# STM32U599 register map
File version: 1.0
CPU: CM33 r0p1, little endian, MPU, FPU, 4 interrupt priority bits
Registers are 32-bit, read-write, reset 0x0 unless marked. A register's access mark holds for its fields unless they carry their own. Offsets are from the block's base; [hi:lo] are bit positions; {n}, {i} and the like mark numbered series.

## GTZC1_MPCBB1
Base 0x40032C00
Same registers: SEC_GTZC1_MPCBB1 0x50032C00
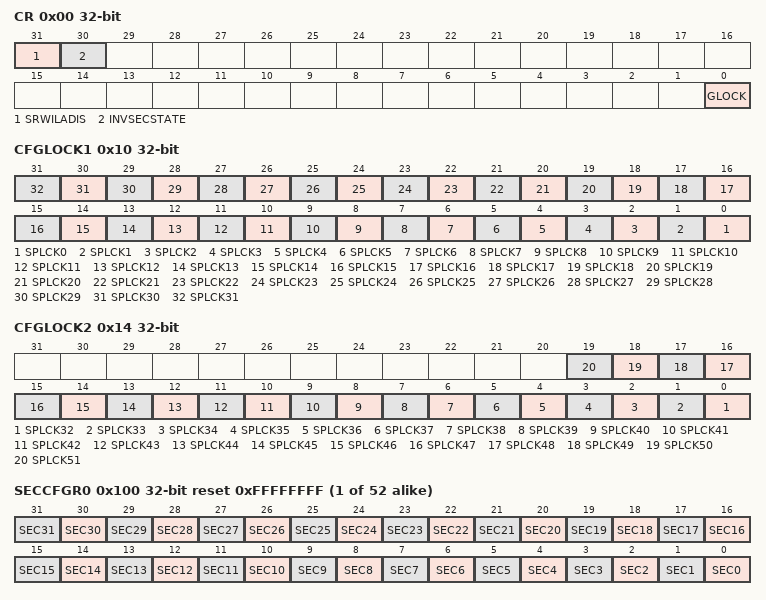
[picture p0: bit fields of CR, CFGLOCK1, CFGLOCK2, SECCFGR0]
0x00 CR — MPCBB control register
  [31] SRWILADIS — secure read/write illegal access disable
  [30] INVSECSTATE — SRAMx clocks security state
  [0] GLOCK — lock the control register of the MPCBB until next reset
0x10 CFGLOCK1 — GTZC1 SRAMz MPCBB configuration lock register 1
  [n] SPLCK{n} (n=0..31) — SPLCK{n}
0x14 CFGLOCK2 — GTZC1 SRAMz MPCBB configuration lock register 2
  [n-32] SPLCK{n} (n=32..51) — SPLCK{n}
{0x100+4i} SECCFGR{i} (i=0..51) reset 0xFFFFFFFF — MPCBBz security configuration for super-block {i} register
  [n] SEC{n} (n=0..31) — SEC{n}
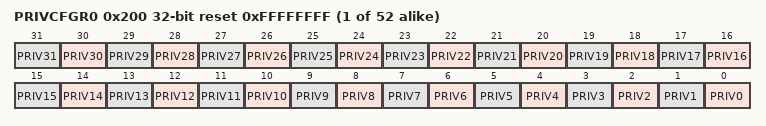
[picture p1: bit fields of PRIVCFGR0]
{0x200+4i} PRIVCFGR{i} (i=0..51) reset 0xFFFFFFFF — MPCBBz privileged configuration for super-block {i} register
  [n] PRIV{n} (n=0..31) — PRIV{n}

## GTZC1_MPCBB2
Base 0x40033000
Same registers: GTZC1_MPCBB3 0x40033400, GTZC1_MPCBB5 0x40033800, SEC_GTZC1_MPCBB2 0x50033000, SEC_GTZC1_MPCBB3 0x50033400, SEC_GTZC1_MPCBB5 0x50033800
Registers as GTZC1_MPCBB1; these are added or differ:
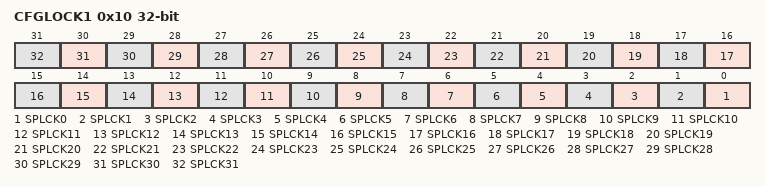
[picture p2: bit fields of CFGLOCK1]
0x10 CFGLOCK1 — GTZC1 SRAMz MPCBB configuration lock register
  [n] SPLCK{n} (n=0..31) — SPLCK{n}

## GTZC2_MPCBB4
Base 0x46023800
Same registers: SEC_GTZC2_MPCBB4 0x56023800
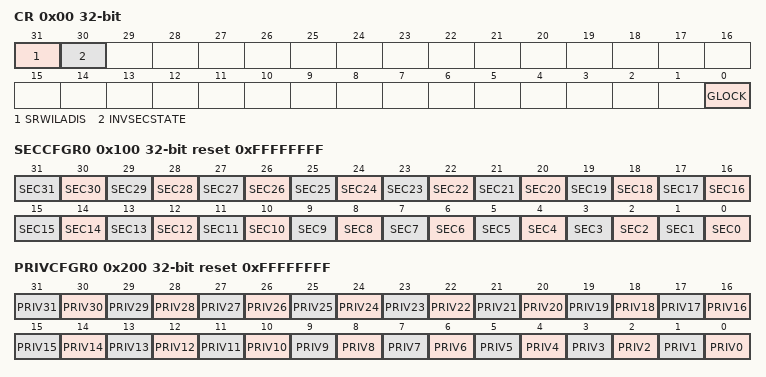
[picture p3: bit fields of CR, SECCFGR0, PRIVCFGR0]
0x00 CR — MPCBB control register
  [31] SRWILADIS — secure read/write illegal access disable
  [30] INVSECSTATE — SRAMx clocks security state
  [0] GLOCK — lock the control register of the MPCBB until next reset
0x10 CFGLOCK — GTZC2 SRAM4 MPCBB configuration lock register
  [n] SPLCK{n} (n=0..0) — Security/privilege configuration lock for super-block {n}
{0x100+4i} SECCFGR{i} (i=0..0) reset 0xFFFFFFFF — MPCBBz security configuration for super-block {i} register
  [n] SEC{n} (n=0..31) — SEC{n}
{0x200+4i} PRIVCFGR{i} (i=0..0) reset 0xFFFFFFFF — MPCBBz privileged configuration for super-block {i} register
  [n] PRIV{n} (n=0..31) — PRIV{n}

## GTZC2_TZSC
Base 0x46023000
Same registers: SEC_GTZC2_TZSC 0x56023000
0x00 TZSC_CR — TZSC control register
  [0] LCK — lock the configuration of GTZC1_TZSC_SECCFGRx and GTZC1_TZSC_PRIVCFGRx registers until next reset
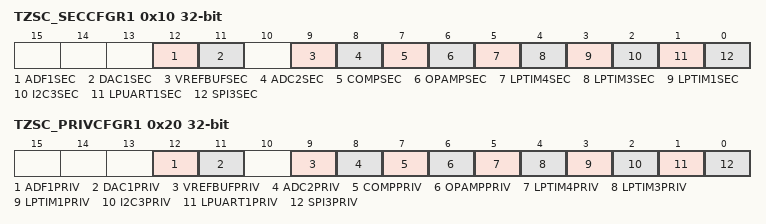
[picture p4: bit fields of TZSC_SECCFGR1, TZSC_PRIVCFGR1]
0x10 TZSC_SECCFGR1 — TZSC secure configuration register 1
  [12] ADF1SEC — secure access mode for ADF1
  [11] DAC1SEC — secure access mode for DAC1
  [9] VREFBUFSEC — secure access mode for VREFBUF
  [8] ADC2SEC — secure access mode for ADC2
  [7] COMPSEC — secure access mode for COMP
  [6] OPAMPSEC — secure access mode for OPAMP
  [5] LPTIM4SEC — secure access mode for LPTIM4
  [4] LPTIM3SEC — secure access mode for LPTIM3
  [3] LPTIM1SEC — secure access mode for LPTIM1
  [2] I2C3SEC — secure access mode for I2C3
  [1] LPUART1SEC — secure access mode for LPUART1
  [0] SPI3SEC — secure access mode for SPI3
0x20 TZSC_PRIVCFGR1 — TZSC privilege configuration register 1
  [12] ADF1PRIV — privileged access mode for ADF1
  [11] DAC1PRIV — privileged access mode for DAC1
  [9] VREFBUFPRIV — privileged access mode for VREFBUF
  [8] ADC2PRIV — privileged access mode for ADC2
  [7] COMPPRIV — privileged access mode for COMP
  [6] OPAMPPRIV — privileged access mode for OPAMP
  [5] LPTIM4PRIV — privileged access mode for LPTIM4
  [4] LPTIM3PRIV — privileged access mode for LPTIM3
  [3] LPTIM1PRIV — privileged access mode for LPTIM1
  [2] I2C3PRIV — privileged access mode for I2C3
  [1] LPUART1PRIV — privileged access mode for LPUART1
  [0] SPI3PRIV — privileged access mode for SPI3

## HASH — Hash processor
Base 0x420C0400
Same registers: SEC_HASH 0x520C0400
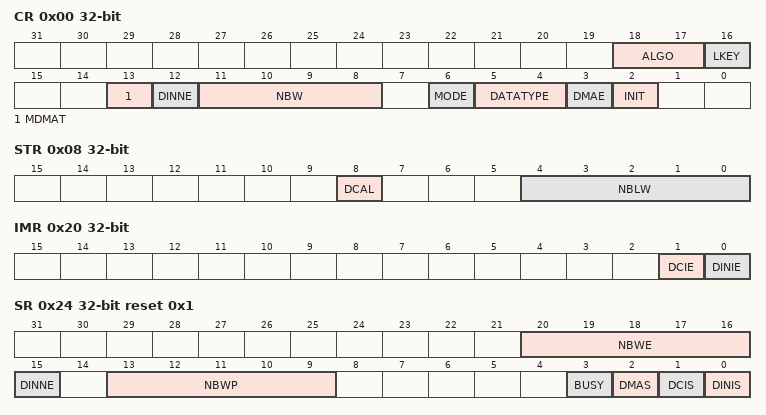
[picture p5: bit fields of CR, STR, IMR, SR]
0x00 CR access per field — control register
  [18:17] ALGO rw — Algorithm selection
  [16] LKEY rw — Long key selection
  [13] MDMAT rw — Multiple DMA Transfers
  [12] DINNE ro — DIN not empty
  [11:8] NBW ro — Number of words already pushed
  [6] MODE rw — Mode selection
  [5:4] DATATYPE rw — Data type selection
  [3] DMAE rw — DMA enable
  [2] INIT wo — Initialize message digest calculation
0x04 DIN wo — data input register
  [31:0] DATAIN — Data input
0x08 STR access per field — start register
  [8] DCAL wo — Digest calculation
  [4:0] NBLW rw — Number of valid bits in the last word of the message
{0xC+4i} HRA{i} ro (i=0..4) — HASH aliased digest register {i}
  [31:0] H{i}
0x20 IMR — interrupt enable register
  [1] DCIE — Digest calculation completion interrupt enable
  [0] DINIE — Data input interrupt enable
0x24 SR access per field reset 0x1 — status register
  [20:16] NBWE ro — Number of words expected
  [15] DINNE ro — DIN not empty
  [13:9] NBWP ro — Number of words already pushed
  [3] BUSY ro — Busy bit
  [2] DMAS ro — DMA Status
  [1] DCIS rw — Digest calculation completion interrupt status
  [0] DINIS rw — Data input interrupt status
{0xF8+4i} CSR{i} (i=0..53) — context swap registers
  [31:0] CS{i}
0x310 HR0 ro — digest register 0
  [31:0] H0
0x314 HR1 ro — digest register 1
  [31:0] H1
0x318 HR2 ro — digest register 4
  [31:0] H2
0x31C HR3 ro — digest register 3
  [31:0] H3
0x320 HR4 ro — digest register 4
  [31:0] H4
{0x310+4i} HR{i} ro (i=5..7) — supplementary digest register {i}
  [31:0] H{i}
